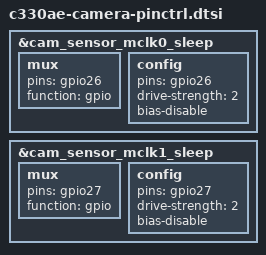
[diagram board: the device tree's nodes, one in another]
&cam_sensor_mclk0_sleep {
	mux {
		pins = "gpio26";
		function = "gpio";
	};

	config {
		pins = "gpio26";
		drive-strength = <2>;
		bias-disable;
	};
};

&cam_sensor_mclk1_sleep {
	mux {
		pins = "gpio27";
		function = "gpio";
	};

	config {
		pins = "gpio27";
		drive-strength = <2>;
		bias-disable;
	};
};
